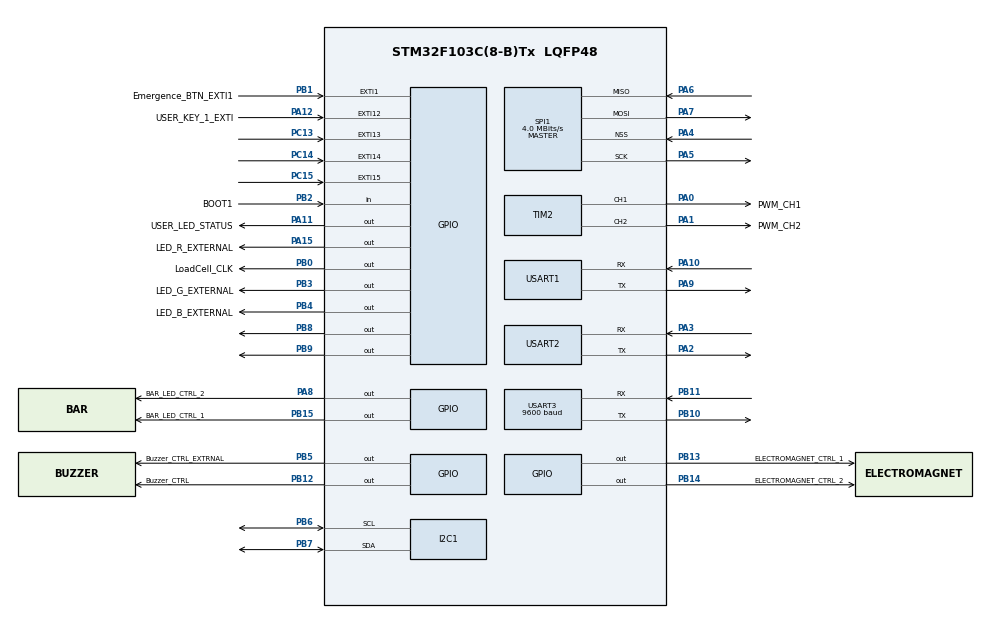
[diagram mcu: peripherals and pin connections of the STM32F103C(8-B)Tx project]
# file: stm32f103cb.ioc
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Mcu.Family=STM32F1
Mcu.Name=STM32F103C(8-B)Tx
Mcu.Package=LQFP48
NVIC.EXTI15_10_IRQn=true\:0\:0\:false\:true\:true\:8\:true
NVIC.EXTI1_IRQn=true\:0\:0\:false\:true\:true\:1\:true
NVIC.PriorityGroup=NVIC_PRIORITYGROUP_4
NVIC.TIM2_IRQn=true\:0\:0\:false\:true\:true\:4\:true
NVIC.USART1_IRQn=true\:0\:0\:false\:true\:true\:5\:true
NVIC.USART2_IRQn=true\:0\:0\:false\:true\:true\:6\:true
NVIC.USART3_IRQn=true\:0\:0\:false\:true\:true\:7\:true
PA0-WKUP.GPIO_Label=PWM_CH1
PA0-WKUP.Signal=S_TIM2_CH1_ETR
PA1.GPIO_Label=PWM_CH2
PA1.Signal=S_TIM2_CH2
PA10.Mode=Asynchronous
PA10.Signal=USART1_RX
PA11.GPIO_Label=USER_LED_STATUS
PA11.Signal=GPIO_Output
PA12.GPIO_Label=USER_KEY_1_EXTI
PA12.Signal=GPXTI12
PA13.Mode=Serial_Wire
PA13.Signal=SYS_JTMS-SWDIO
PA14.Mode=Serial_Wire
PA14.Signal=SYS_JTCK-SWCLK
PA15.GPIO_Label=LED_R_EXTERNAL
PA15.Signal=GPIO_Output
PA2.Mode=Asynchronous
PA2.Signal=USART2_TX
PA3.Mode=Asynchronous
PA3.Signal=USART2_RX
PA4.Mode=NSS_Signal_Hard_Input
PA4.Signal=SPI1_NSS
PA5.Mode=Full_Duplex_Master
PA5.Signal=SPI1_SCK
PA6.Mode=Full_Duplex_Master
PA6.Signal=SPI1_MISO
PA7.Mode=Full_Duplex_Master
PA7.Signal=SPI1_MOSI
PA8.GPIO_Label=BAR_LED_CTRL_2
PA8.Signal=GPIO_Output
PA9.Mode=Asynchronous
PA9.Signal=USART1_TX
PB0.GPIO_Label=LoadCell_CLK
PB0.Signal=GPIO_Output
PB1.GPIO_Label=Emergence_BTN_EXTI1
PB1.Signal=GPXTI1
PB10.Mode=Asynchronous
PB10.Signal=USART3_TX
PB11.Mode=Asynchronous
PB11.Signal=USART3_RX
PB12.GPIO_Label=Buzzer_CTRL
PB12.Signal=GPIO_Output
PB13.GPIO_Label=ELECTROMAGNET_CTRL_1
PB13.Signal=GPIO_Output
PB14.GPIO_Label=ELECTROMAGNET_CTRL_2
PB14.Signal=GPIO_Output
PB15.GPIO_Label=BAR_LED_CTRL_1
PB15.Signal=GPIO_Output
PB2.GPIO_Label=BOOT1
PB2.Signal=GPIO_Input
PB3.GPIO_Label=LED_G_EXTERNAL
PB3.Signal=GPIO_Output
PB4.GPIO_Label=LED_B_EXTERNAL
PB4.Signal=GPIO_Output
PB5.GPIO_Label=Buzzer_CTRL_EXTRNAL
PB5.PinState=GPIO_PIN_SET
PB5.Signal=GPIO_Output
PB6.Mode=I2C
PB6.Signal=I2C1_SCL
PB7.Mode=I2C
PB7.Signal=I2C1_SDA
PB8.Signal=GPIO_Output
PB9.Signal=GPIO_Output
PC13-TAMPER-RTC.Signal=GPXTI13
PC14-OSC32_IN.Signal=GPXTI14
PC15-OSC32_OUT.Signal=GPXTI15
PD0-OSC_IN.Mode=HSE-External-Oscillator
PD0-OSC_IN.Signal=RCC_OSC_IN
PD1-OSC_OUT.Mode=HSE-External-Oscillator
PD1-OSC_OUT.Signal=RCC_OSC_OUT
ProjectManager.HeapSize=0x200
ProjectManager.StackSize=0x400
ProjectManager.TargetToolchain=Makefile
RCC.APB1Freq_Value=8000000
RCC.APB2Freq_Value=8000000
SH.S_TIM2_CH1_ETR.0=TIM2_CH1,PWM Generation1 CH1
SH.S_TIM2_CH2.0=TIM2_CH2,PWM Generation2 CH2
SPI1.CalculateBaudRate=4.0 MBits/s
SPI1.Direction=SPI_DIRECTION_2LINES
SPI1.Mode=SPI_MODE_MASTER
SPI1.VirtualNSS=VM_NSSHARD
SPI1.VirtualType=VM_MASTER
TIM2.Channel-PWM\ Generation1\ CH1=TIM_CHANNEL_1
TIM2.Channel-PWM\ Generation2\ CH2=TIM_CHANNEL_2
USART1.VirtualMode=VM_ASYNC
USART2.VirtualMode=VM_ASYNC
USART3.BaudRate=9600
USART3.VirtualMode=VM_ASYNC
board=custom

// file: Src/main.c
/**
  ******************************************************************************
  * @file           : main.c
  * @brief          : Main program body
  ******************************************************************************
  ** This notice applies to any and all portions of this file
  * that are not between comment pairs USER CODE BEGIN and
  * USER CODE END. Other portions of this file, whether
  * inserted by the user or by software development tools
  * are owned by their respective copyright owners.
  *
  * COPYRIGHT(c) 2018 STMicroelectronics
  *
  * Redistribution and use in source and binary forms, with or without modification,
  * are permitted provided that the following conditions are met:
  *   1. Redistributions of source code must retain the above copyright notice,
  *      this list of conditions and the following disclaimer.
  *   2. Redistributions in binary form must reproduce the above copyright notice,
  *      this list of conditions and the following disclaimer in the documentation
  *      and/or other materials provided with the distribution.
  *   3. Neither the name of STMicroelectronics nor the names of its contributors
  *      may be used to endorse or promote products derived from this software
  *      without specific prior written permission.
  *
  * THIS SOFTWARE IS PROVIDED BY THE COPYRIGHT HOLDERS AND CONTRIBUTORS "AS IS"
  * AND ANY EXPRESS OR IMPLIED WARRANTIES, INCLUDING, BUT NOT LIMITED TO, THE
  * IMPLIED WARRANTIES OF MERCHANTABILITY AND FITNESS FOR A PARTICULAR PURPOSE ARE
  * DISCLAIMED. IN NO EVENT SHALL THE COPYRIGHT HOLDER OR CONTRIBUTORS BE LIABLE
  * FOR ANY DIRECT, INDIRECT, INCIDENTAL, SPECIAL, EXEMPLARY, OR CONSEQUENTIAL
  * DAMAGES (INCLUDING, BUT NOT LIMITED TO, PROCUREMENT OF SUBSTITUTE GOODS OR
  * SERVICES; LOSS OF USE, DATA, OR PROFITS; OR BUSINESS INTERRUPTION) HOWEVER
  * CAUSED AND ON ANY THEORY OF LIABILITY, WHETHER IN CONTRACT, STRICT LIABILITY,
  * OR TORT (INCLUDING NEGLIGENCE OR OTHERWISE) ARISING IN ANY WAY OUT OF THE USE
  * OF THIS SOFTWARE, EVEN IF ADVISED OF THE POSSIBILITY OF SUCH DAMAGE.
  *
  ******************************************************************************
  */
#include "main.h"
#include "stm32f1xx_hal.h"

/* USER CODE BEGIN Includes */
#include "dev/sensor/hc_06.h"
/* USER CODE END Includes */

I2C_HandleTypeDef hi2c1;

SPI_HandleTypeDef hspi1;

TIM_HandleTypeDef htim2;

UART_HandleTypeDef huart1;
UART_HandleTypeDef huart2;
UART_HandleTypeDef huart3;

/* USER CODE BEGIN PV */
/* Private variables ---------------------------------------------------------*/

/* USER CODE END PV */

void SystemClock_Config(void);
static void MX_GPIO_Init(void);
static void MX_I2C1_Init(void);
static void MX_TIM2_Init(void);
static void MX_USART1_UART_Init(void);
static void MX_USART2_UART_Init(void);
static void MX_USART3_UART_Init(void);
static void MX_SPI1_Init(void);
static void MX_NVIC_Init(void);

void HAL_TIM_MspPostInit(TIM_HandleTypeDef *htim);

/* USER CODE BEGIN PFP */
/* Private function prototypes -----------------------------------------------*/

/* USER CODE END PFP */

/* USER CODE BEGIN 0 */
int _write(int file, char* data, int len) {
	HAL_StatusTypeDef status =
		HAL_UART_Transmit(&huart1, (uint8_t*)data, len, 1000);
	return (status == HAL_OK ? len : 0);
}

void HAL_UART_RxCpltCallback(UART_HandleTypeDef *huart) {
	hc06_receive_byte();
}
/* USER CODE END 0 */

int main(void)
{

  /* MCU Configuration----------------------------------------------------------*/

  /* Reset of all peripherals, Initializes the Flash interface and the Systick. */
  HAL_Init();

  /* Configure the system clock */
  SystemClock_Config();

  /* Initialize all configured peripherals */
  MX_GPIO_Init();
  MX_I2C1_Init();
  MX_TIM2_Init();
  MX_USART1_UART_Init();
  MX_USART2_UART_Init();
  MX_USART3_UART_Init();
  MX_SPI1_Init();

  /* Initialize interrupts */
  MX_NVIC_Init();
  /* USER CODE BEGIN 2 */
  hc06_init(&huart3);
  //hc06_init(&huart1);
  /* USER CODE END 2 */

  /* Infinite loop */
  while (1)
  {

  }

}

void SystemClock_Config(void)
{

  RCC_OscInitTypeDef RCC_OscInitStruct;
  RCC_ClkInitTypeDef RCC_ClkInitStruct;

    /**Initializes the CPU, AHB and APB busses clocks
    */
  RCC_OscInitStruct.OscillatorType = RCC_OSCILLATORTYPE_HSI;
  RCC_OscInitStruct.HSIState = RCC_HSI_ON;
  RCC_OscInitStruct.HSICalibrationValue = 16;
  RCC_OscInitStruct.PLL.PLLState = RCC_PLL_NONE;
  if (HAL_RCC_OscConfig(&RCC_OscInitStruct) != HAL_OK)
  {
    _Error_Handler(__FILE__, __LINE__);
  }

    /**Initializes the CPU, AHB and APB busses clocks
    */
  RCC_ClkInitStruct.ClockType = RCC_CLOCKTYPE_HCLK|RCC_CLOCKTYPE_SYSCLK
                              |RCC_CLOCKTYPE_PCLK1|RCC_CLOCKTYPE_PCLK2;
  RCC_ClkInitStruct.SYSCLKSource = RCC_SYSCLKSOURCE_HSI;
  RCC_ClkInitStruct.AHBCLKDivider = RCC_SYSCLK_DIV1;
  RCC_ClkInitStruct.APB1CLKDivider = RCC_HCLK_DIV1;
  RCC_ClkInitStruct.APB2CLKDivider = RCC_HCLK_DIV1;

  if (HAL_RCC_ClockConfig(&RCC_ClkInitStruct, FLASH_LATENCY_0) != HAL_OK)
  {
    _Error_Handler(__FILE__, __LINE__);
  }

    /**Configure the Systick interrupt time
    */
  HAL_SYSTICK_Config(HAL_RCC_GetHCLKFreq()/1000);

    /**Configure the Systick
    */
  HAL_SYSTICK_CLKSourceConfig(SYSTICK_CLKSOURCE_HCLK);

  /* SysTick_IRQn interrupt configuration */
  HAL_NVIC_SetPriority(SysTick_IRQn, 0, 0);
}

/**
  * @brief NVIC Configuration.
  * @retval None
  */
static void MX_NVIC_Init(void)
{
  /* EXTI1_IRQn interrupt configuration */
  HAL_NVIC_SetPriority(EXTI1_IRQn, 0, 0);
  HAL_NVIC_EnableIRQ(EXTI1_IRQn);
  /* TIM2_IRQn interrupt configuration */
  HAL_NVIC_SetPriority(TIM2_IRQn, 0, 0);
  HAL_NVIC_EnableIRQ(TIM2_IRQn);
  /* USART1_IRQn interrupt configuration */
  HAL_NVIC_SetPriority(USART1_IRQn, 0, 0);
  HAL_NVIC_EnableIRQ(USART1_IRQn);
  /* USART2_IRQn interrupt configuration */
  HAL_NVIC_SetPriority(USART2_IRQn, 0, 0);
  HAL_NVIC_EnableIRQ(USART2_IRQn);
  /* USART3_IRQn interrupt configuration */
  HAL_NVIC_SetPriority(USART3_IRQn, 0, 0);
  HAL_NVIC_EnableIRQ(USART3_IRQn);
  /* EXTI15_10_IRQn interrupt configuration */
  HAL_NVIC_SetPriority(EXTI15_10_IRQn, 0, 0);
  HAL_NVIC_EnableIRQ(EXTI15_10_IRQn);
}

/* I2C1 init function */
static void MX_I2C1_Init(void)
{

  hi2c1.Instance = I2C1;
  hi2c1.Init.ClockSpeed = 100000;
  hi2c1.Init.DutyCycle = I2C_DUTYCYCLE_2;
  hi2c1.Init.OwnAddress1 = 0;
  hi2c1.Init.AddressingMode = I2C_ADDRESSINGMODE_7BIT;
  hi2c1.Init.DualAddressMode = I2C_DUALADDRESS_DISABLE;
  hi2c1.Init.OwnAddress2 = 0;
  hi2c1.Init.GeneralCallMode = I2C_GENERALCALL_DISABLE;
  hi2c1.Init.NoStretchMode = I2C_NOSTRETCH_DISABLE;
  if (HAL_I2C_Init(&hi2c1) != HAL_OK)
  {
    _Error_Handler(__FILE__, __LINE__);
  }

}

/* SPI1 init function */
static void MX_SPI1_Init(void)
{

  /* SPI1 parameter configuration*/
  hspi1.Instance = SPI1;
  hspi1.Init.Mode = SPI_MODE_MASTER;
  hspi1.Init.Direction = SPI_DIRECTION_2LINES;
  hspi1.Init.DataSize = SPI_DATASIZE_8BIT;
  hspi1.Init.CLKPolarity = SPI_POLARITY_LOW;
  hspi1.Init.CLKPhase = SPI_PHASE_1EDGE;
  hspi1.Init.NSS = SPI_NSS_HARD_INPUT;
  hspi1.Init.BaudRatePrescaler = SPI_BAUDRATEPRESCALER_2;
  hspi1.Init.FirstBit = SPI_FIRSTBIT_MSB;
  hspi1.Init.TIMode = SPI_TIMODE_DISABLE;
  hspi1.Init.CRCCalculation = SPI_CRCCALCULATION_DISABLE;
  hspi1.Init.CRCPolynomial = 10;
  if (HAL_SPI_Init(&hspi1) != HAL_OK)
  {
    _Error_Handler(__FILE__, __LINE__);
  }

}

/* TIM2 init function */
static void MX_TIM2_Init(void)
{

  TIM_MasterConfigTypeDef sMasterConfig;
  TIM_OC_InitTypeDef sConfigOC;

  htim2.Instance = TIM2;
  htim2.Init.Prescaler = 0;
  htim2.Init.CounterMode = TIM_COUNTERMODE_UP;
  htim2.Init.Period = 0;
  htim2.Init.ClockDivision = TIM_CLOCKDIVISION_DIV1;
  htim2.Init.AutoReloadPreload = TIM_AUTORELOAD_PRELOAD_DISABLE;
  if (HAL_TIM_PWM_Init(&htim2) != HAL_OK)
  {
    _Error_Handler(__FILE__, __LINE__);
  }

  sMasterConfig.MasterOutputTrigger = TIM_TRGO_RESET;
  sMasterConfig.MasterSlaveMode = TIM_MASTERSLAVEMODE_DISABLE;
  if (HAL_TIMEx_MasterConfigSynchronization(&htim2, &sMasterConfig) != HAL_OK)
  {
    _Error_Handler(__FILE__, __LINE__);
  }

  sConfigOC.OCMode = TIM_OCMODE_PWM1;
  sConfigOC.Pulse = 0;
  sConfigOC.OCPolarity = TIM_OCPOLARITY_HIGH;
  sConfigOC.OCFastMode = TIM_OCFAST_DISABLE;
  if (HAL_TIM_PWM_ConfigChannel(&htim2, &sConfigOC, TIM_CHANNEL_1) != HAL_OK)
  {
    _Error_Handler(__FILE__, __LINE__);
  }

  if (HAL_TIM_PWM_ConfigChannel(&htim2, &sConfigOC, TIM_CHANNEL_2) != HAL_OK)
  {
    _Error_Handler(__FILE__, __LINE__);
  }

  HAL_TIM_MspPostInit(&htim2);

}

/* USART1 init function */
static void MX_USART1_UART_Init(void)
{

  huart1.Instance = USART1;
  huart1.Init.BaudRate = 115200;
  huart1.Init.WordLength = UART_WORDLENGTH_8B;
  huart1.Init.StopBits = UART_STOPBITS_1;
  huart1.Init.Parity = UART_PARITY_NONE;
  huart1.Init.Mode = UART_MODE_TX_RX;
  huart1.Init.HwFlowCtl = UART_HWCONTROL_NONE;
  huart1.Init.OverSampling = UART_OVERSAMPLING_16;
  if (HAL_UART_Init(&huart1) != HAL_OK)
  {
    _Error_Handler(__FILE__, __LINE__);
  }

}

/* USART2 init function */
static void MX_USART2_UART_Init(void)
{

  huart2.Instance = USART2;
  huart2.Init.BaudRate = 115200;
  huart2.Init.WordLength = UART_WORDLENGTH_8B;
  huart2.Init.StopBits = UART_STOPBITS_1;
  huart2.Init.Parity = UART_PARITY_NONE;
  huart2.Init.Mode = UART_MODE_TX_RX;
  huart2.Init.HwFlowCtl = UART_HWCONTROL_NONE;
  huart2.Init.OverSampling = UART_OVERSAMPLING_16;
  if (HAL_UART_Init(&huart2) != HAL_OK)
  {
    _Error_Handler(__FILE__, __LINE__);
  }

}

/* USART3 init function */
static void MX_USART3_UART_Init(void)
{

  huart3.Instance = USART3;
  huart3.Init.BaudRate = 9600;
  huart3.Init.WordLength = UART_WORDLENGTH_8B;
  huart3.Init.StopBits = UART_STOPBITS_1;
  huart3.Init.Parity = UART_PARITY_NONE;
  huart3.Init.Mode = UART_MODE_TX_RX;
  huart3.Init.HwFlowCtl = UART_HWCONTROL_NONE;
  huart3.Init.OverSampling = UART_OVERSAMPLING_16;
  if (HAL_UART_Init(&huart3) != HAL_OK)
  {
    _Error_Handler(__FILE__, __LINE__);
  }

}

/** Configure pins as
        * Analog
        * Input
        * Output
        * EVENT_OUT
        * EXTI
*/
static void MX_GPIO_Init(void)
{

  GPIO_InitTypeDef GPIO_InitStruct;

  /* GPIO Ports Clock Enable */
  __HAL_RCC_GPIOC_CLK_ENABLE();
  __HAL_RCC_GPIOD_CLK_ENABLE();
  __HAL_RCC_GPIOA_CLK_ENABLE();
  __HAL_RCC_GPIOB_CLK_ENABLE();

  /*Configure GPIO pin Output Level */
  HAL_GPIO_WritePin(GPIOB, LoadCell_CLK_Pin|Buzzer_CTRL_Pin|ELECTROMAGNET_CTRL_1_Pin|ELECTROMAGNET_CTRL_2_Pin
                          |BAR_LED_CTRL_1_Pin|LED_G_EXTERNAL_Pin|LED_B_EXTERNAL_Pin|GPIO_PIN_8
                          |GPIO_PIN_9, GPIO_PIN_RESET);

  /*Configure GPIO pin Output Level */
  HAL_GPIO_WritePin(GPIOA, BAR_LED_CTRL_2_Pin|USER_LED_STATUS_Pin|LED_R_EXTERNAL_Pin, GPIO_PIN_RESET);

  /*Configure GPIO pin Output Level */
  HAL_GPIO_WritePin(Buzzer_CTRL_EXTRNAL_GPIO_Port, Buzzer_CTRL_EXTRNAL_Pin, GPIO_PIN_SET);

  /*Configure GPIO pins : PC13 PC14 PC15 */
  GPIO_InitStruct.Pin = GPIO_PIN_13|GPIO_PIN_14|GPIO_PIN_15;
  GPIO_InitStruct.Mode = GPIO_MODE_IT_RISING;
  GPIO_InitStruct.Pull = GPIO_NOPULL;
  HAL_GPIO_Init(GPIOC, &GPIO_InitStruct);

  /*Configure GPIO pins : LoadCell_CLK_Pin Buzzer_CTRL_Pin ELECTROMAGNET_CTRL_1_Pin ELECTROMAGNET_CTRL_2_Pin
                           BAR_LED_CTRL_1_Pin LED_G_EXTERNAL_Pin LED_B_EXTERNAL_Pin Buzzer_CTRL_EXTRNAL_Pin
                           PB8 PB9 */
  GPIO_InitStruct.Pin = LoadCell_CLK_Pin|Buzzer_CTRL_Pin|ELECTROMAGNET_CTRL_1_Pin|ELECTROMAGNET_CTRL_2_Pin
                          |BAR_LED_CTRL_1_Pin|LED_G_EXTERNAL_Pin|LED_B_EXTERNAL_Pin|Buzzer_CTRL_EXTRNAL_Pin
                          |GPIO_PIN_8|GPIO_PIN_9;
  GPIO_InitStruct.Mode = GPIO_MODE_OUTPUT_PP;
  GPIO_InitStruct.Pull = GPIO_NOPULL;
  GPIO_InitStruct.Speed = GPIO_SPEED_FREQ_LOW;
  HAL_GPIO_Init(GPIOB, &GPIO_InitStruct);

  /*Configure GPIO pin : Emergence_BTN_EXTI1_Pin */
  GPIO_InitStruct.Pin = Emergence_BTN_EXTI1_Pin;
  GPIO_InitStruct.Mode = GPIO_MODE_IT_RISING;
  GPIO_InitStruct.Pull = GPIO_NOPULL;
  HAL_GPIO_Init(Emergence_BTN_EXTI1_GPIO_Port, &GPIO_InitStruct);

  /*Configure GPIO pin : BOOT1_Pin */
  GPIO_InitStruct.Pin = BOOT1_Pin;
  GPIO_InitStruct.Mode = GPIO_MODE_INPUT;
  GPIO_InitStruct.Pull = GPIO_NOPULL;
  HAL_GPIO_Init(BOOT1_GPIO_Port, &GPIO_InitStruct);

  /*Configure GPIO pins : BAR_LED_CTRL_2_Pin USER_LED_STATUS_Pin LED_R_EXTERNAL_Pin */
  GPIO_InitStruct.Pin = BAR_LED_CTRL_2_Pin|USER_LED_STATUS_Pin|LED_R_EXTERNAL_Pin;
  GPIO_InitStruct.Mode = GPIO_MODE_OUTPUT_PP;
  GPIO_InitStruct.Pull = GPIO_NOPULL;
  GPIO_InitStruct.Speed = GPIO_SPEED_FREQ_LOW;
  HAL_GPIO_Init(GPIOA, &GPIO_InitStruct);

  /*Configure GPIO pin : USER_KEY_1_EXTI_Pin */
  GPIO_InitStruct.Pin = USER_KEY_1_EXTI_Pin;
  GPIO_InitStruct.Mode = GPIO_MODE_IT_RISING;
  GPIO_InitStruct.Pull = GPIO_NOPULL;
  HAL_GPIO_Init(USER_KEY_1_EXTI_GPIO_Port, &GPIO_InitStruct);

}

void _Error_Handler(char *file, int line)
{
  while(1)
  {
  }
}

/************************ (C) COPYRIGHT STMicroelectronics *****END OF FILE****/
